# SFR__Special_Function_Registers_2 register map
Vendor: Texas Instruments
Peripheral module from a debugger description file (folder msp430).
Registers are 16-bit, read-write, reset 0x0 unless marked. A register's access mark holds for its fields unless they carry their own. Offsets are as the file gives them; lines under a group give offsets from that group; [hi:lo] are bit positions; {n}, {i} and the like mark numbered series; 'fields as' and 'values as' point back to an identical list; <NAME> marks a mode.

## SFR_Special_Function_Registers
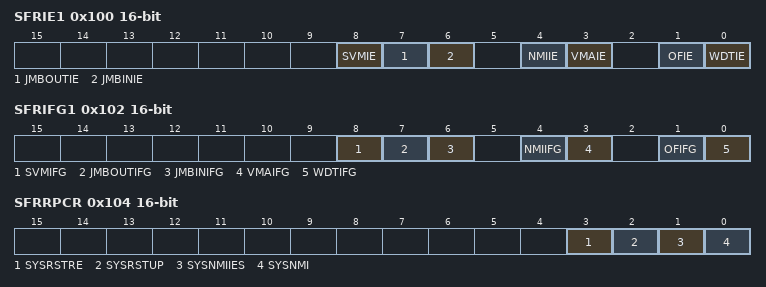
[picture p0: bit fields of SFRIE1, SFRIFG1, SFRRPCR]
0x100 SFRIE1 — Interrupt Enable 1
  [8] SVMIE — SVM Interrupt Enable
  [7] JMBOUTIE — JTAG Mail Box output Interrupt Enable
  [6] JMBINIE — JTAG Mail Box input Interrupt Enable
  [4] NMIIE — NMI Interrupt Enable
  [3] VMAIE — Vacant Memory Interrupt Enable
  [1] OFIE — Osc Fault Enable
  [0] WDTIE — WDT Interrupt Enable
0x102 SFRIFG1 — Interrupt Flag 1
  [8] SVMIFG — SVM Interrupt Flag
  [7] JMBOUTIFG — JTAG Mail Box output Interrupt Flag
  [6] JMBINIFG — JTAG Mail Box input Interrupt Flag
  [4] NMIIFG — NMI Interrupt Flag
  [3] VMAIFG — Vacant Memory Interrupt Flag
  [1] OFIFG — Osc Fault Flag
  [0] WDTIFG — WDT Interrupt Flag
0x104 SFRRPCR — RESET Pin Control Register
  [3] SYSRSTRE — RESET Pin Resistor enable
  [2] SYSRSTUP — RESET Pin pull down/up select
  [1] SYSNMIIES — NMI edge select
  [0] SYSNMI — NMI select
